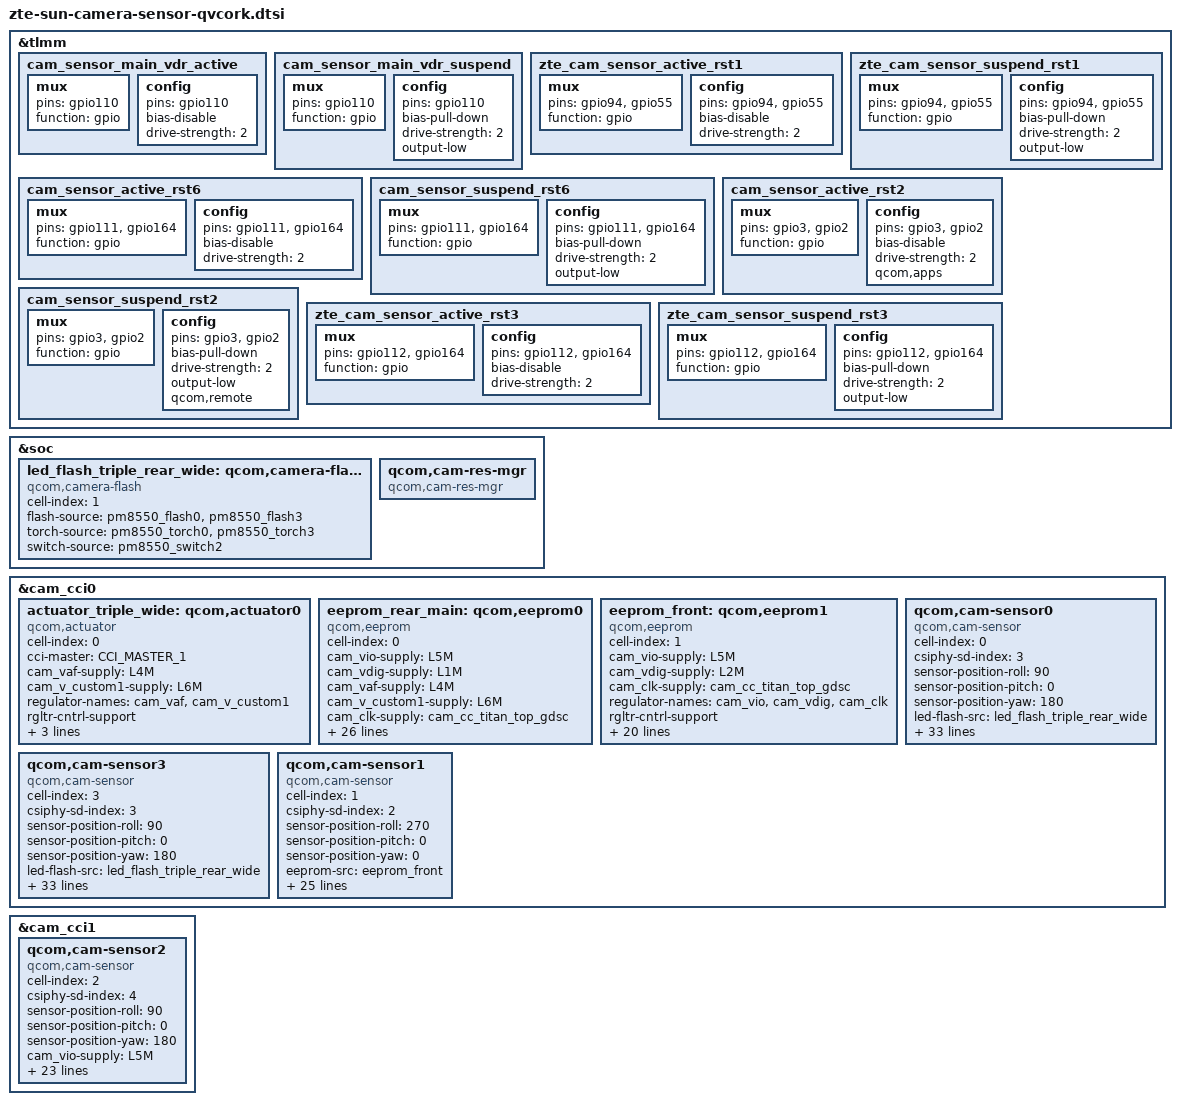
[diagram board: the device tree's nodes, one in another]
#include <dt-bindings/msm-camera.h>
&tlmm {
	cam_sensor_main_vdr_active: cam_sensor_main_vdr_active {
		mux {
			pins = "gpio110";
			function = "gpio";
		};
		config {
			pins = "gpio110";
			bias-disable; /* NO PULL */
			drive-strength = <2>; /* 2 MA */
		};
	};

	cam_sensor_main_vdr_suspend: cam_sensor_main_vdr_suspend {
		mux {
			pins ="gpio110";
			function = "gpio";
		};

		config {
			pins = "gpio110";
			bias-pull-down; /* PULL DOWN */
			drive-strength = <2>; /* 2 MA */
			output-low;
		};
	};

	zte_cam_sensor_active_rst1: zte_cam_sensor_active_rst1 {
		/* RESET 2 */
		mux {
			pins = "gpio94", "gpio55";
			function = "gpio";
		};

		config {
			pins = "gpio94", "gpio55";
			bias-disable; /* No PULL */
			drive-strength = <2>; /* 2 MA */
		};
	};

	zte_cam_sensor_suspend_rst1: zte_cam_sensor_suspend_rst1 {
		/* RESET 2 */
		mux {
			pins = "gpio94", "gpio55";
			function = "gpio";
		};

		config {
			pins = "gpio94", "gpio55";
			bias-pull-down; /* PULL DOWN */
			drive-strength = <2>; /* 2 MA */
			output-low;
		};
	};

	cam_sensor_active_rst6: cam_sensor_active_rst6 {
		/* RESET 2 */
		mux {
			pins = "gpio111", "gpio164";
			function = "gpio";
		};

		config {
			pins = "gpio111", "gpio164";
			bias-disable; /* No PULL */
			drive-strength = <2>; /* 2 MA */
		};
	};

	cam_sensor_suspend_rst6: cam_sensor_suspend_rst6 {
		/* RESET 2 */
		mux {
			pins = "gpio111", "gpio164";
			function = "gpio";
		};

		config {
			pins = "gpio111", "gpio164";
			bias-pull-down; /* PULL DOWN */
			drive-strength = <2>; /* 2 MA */
			output-low;
		};
	};

	cam_sensor_active_rst2: cam_sensor_active_rst2 {
		mux {
			pins = "gpio3", "gpio2";
			function = "gpio";
		};

		config {
			pins = "gpio3", "gpio2";
			bias-disable; /* No PULL */
			drive-strength = <2>; /* 2 MA */
			qcom,apps;
		};
	};

	cam_sensor_suspend_rst2: cam_sensor_suspend_rst2 {
		mux {
			pins = "gpio3", "gpio2";
			function = "gpio";
		};

		config {
			pins = "gpio3", "gpio2";
			bias-pull-down; /* PULL DOWN */
			drive-strength = <2>; /* 2 MA */
			output-low;
			qcom,remote;
		};
	};

	zte_cam_sensor_active_rst3: zte_cam_sensor_active_rst3 {
		/* RESET 2 */
		mux {
			pins = "gpio112", "gpio164";
			function = "gpio";
		};

		config {
			pins = "gpio112", "gpio164";
			bias-disable; /* No PULL */
			drive-strength = <2>; /* 2 MA */
		};
	};

	zte_cam_sensor_suspend_rst3: zte_cam_sensor_suspend_rst3 {
		/* RESET 2 */
		mux {
			pins = "gpio112", "gpio164";
			function = "gpio";
		};

		config {
			pins = "gpio112", "gpio164";
			bias-pull-down; /* PULL DOWN */
			drive-strength = <2>; /* 2 MA */
			output-low;
		};
	};
};

&soc {
	led_flash_triple_rear_wide: qcom,camera-flash1 {
		cell-index = <1>;
		compatible = "qcom,camera-flash";
		flash-source = <&pm8550_flash0 &pm8550_flash3>;
		torch-source = <&pm8550_torch0 &pm8550_torch3>;
		switch-source = <&pm8550_switch2>;
		status = "ok";
	};

	qcom,cam-res-mgr {
		compatible = "qcom,cam-res-mgr";
		status = "ok";
	};
};

&cam_cci0 {
	actuator_triple_wide: qcom,actuator0 {
		cell-index = <0>;
		compatible = "qcom,actuator";
		cci-master = <CCI_MASTER_1>;
		cam_vaf-supply = <&L4M>;
		cam_v_custom1-supply = <&L6M>;
		regulator-names = "cam_vaf", "cam_v_custom1";
		rgltr-cntrl-support;
		rgltr-min-voltage = <2800000 2800000>;
		rgltr-max-voltage = <2800000 2800000>;
		rgltr-load-current = <67700 140000>;
	};
	eeprom_rear_main: qcom,eeprom0 {
		cell-index = <0>;
		compatible = "qcom,eeprom";
		cam_vio-supply = <&L5M>;
		cam_vdig-supply = <&L1M>;
		cam_vaf-supply = <&L4M>;
		cam_v_custom1-supply = <&L6M>;
		cam_clk-supply = <&cam_cc_titan_top_gdsc>;
		regulator-names = "cam_vio", "cam_vdig", "cam_vaf", "cam_v_custom1", "cam_clk";
		rgltr-cntrl-support;
		rgltr-min-voltage = <1800000 1104000 2800000 2800000 0>;
		rgltr-max-voltage = <1800000 1104000 2800000 2800000 0>;
		rgltr-load-current = <155000 680000 67700 140000 0>;
		gpio-no-mux = <0>;
		pinctrl-names = "cam_default", "cam_suspend";
		pinctrl-0 = <&cam_sensor_mclk1_active
			&zte_cam_sensor_active_rst1>;
		pinctrl-1 = <&cam_sensor_mclk1_suspend
			&zte_cam_sensor_suspend_rst1>;
		gpios = <&tlmm 90 0>,
			<&tlmm 94 0>,
			<&tlmm 55 0>;
		gpio-reset = <1>;
		gpio-custom1 = <2>;
		gpio-req-tbl-num = <0 1 2>;
		gpio-req-tbl-flags = <1 0 0>;
		gpio-req-tbl-label = "CAMIF_MCLK1",
					"CAM_RESET1",
					"CAM_VANA1";
		cci-master = <CCI_MASTER_1>;
		clocks = <&cambistmclkcc CAM_BIST_MCLK_CC_MCLK1_CLK>;
		clock-names = "cam_clk";
		clock-cntl-level = "nominal";
		clock-rates = <24000000>;
		status = "ok";
	};

	eeprom_front: qcom,eeprom1 {
		cell-index = <1>;
		compatible = "qcom,eeprom";
		cam_vio-supply = <&L5M>;
		cam_vdig-supply = <&L2M>;
		cam_clk-supply = <&cam_cc_titan_top_gdsc>;
		regulator-names = "cam_vio", "cam_vdig", "cam_clk";
		rgltr-cntrl-support;
		rgltr-min-voltage = <1800000 1056000 0>;
		rgltr-max-voltage = <1800000 1056000 0>;
		rgltr-load-current = <4000 260700 0>;
		gpio-no-mux = <0>;
		pinctrl-names = "cam_default", "cam_suspend";
		pinctrl-0 = <&cam_sensor_mclk4_active
				 &cam_sensor_active_rst6>;
		pinctrl-1 = <&cam_sensor_mclk4_suspend
				 &cam_sensor_suspend_rst6>;
		gpios = <&tlmm 93 0>,
			<&tlmm 111 0>,
			<&tlmm 164 0>;
		gpio-reset = <1>;
		gpio-custom1 = <2>;
		gpio-req-tbl-num = <0 1 2>;
		gpio-req-tbl-flags = <1 0 0>;
		gpio-req-tbl-label = "CAMIF_MCLK4",
					"CAM_RESET6",
					"CAM_VANA6";
		cci-master = <CCI_MASTER_0>;
		clocks = <&cambistmclkcc CAM_BIST_MCLK_CC_MCLK4_CLK>;
		clock-names = "cam_clk";
		clock-cntl-level = "nominal";
		clock-rates = <24000000>;
		status = "ok";
	};

	qcom,cam-sensor0 {
		cell-index = <0>;
		compatible = "qcom,cam-sensor";
		csiphy-sd-index = <3>;
		sensor-position-roll = <90>;
		sensor-position-pitch = <0>;
		sensor-position-yaw = <180>;
		led-flash-src = <&led_flash_triple_rear_wide>;
		eeprom-src = <&eeprom_rear_main>;
		actuator-src = <&actuator_triple_wide>;
		cam_vio-supply = <&L5M>;
		cam_vdig-supply = <&L1M>;
		cam_vaf-supply = <&L4M>;
		cam_v_custom1-supply = <&L6M>;
		cam_clk-supply = <&cam_cc_titan_top_gdsc>;
		regulator-names = "cam_vio", "cam_vdig", "cam_vaf", "cam_v_custom1", "cam_clk";
		rgltr-cntrl-support;
		rgltr-min-voltage = <1800000 1104000 2800000 2800000 0>;
		rgltr-max-voltage = <1800000 1104000 2800000 2800000 0>;
		rgltr-load-current = <155000 680000 67700 140000 0>;
		gpio-no-mux = <0>;
		pinctrl-names = "cam_default", "cam_suspend";
		pinctrl-0 = <&cam_sensor_mclk1_active
			&zte_cam_sensor_active_rst1>;
		pinctrl-1 = <&cam_sensor_mclk1_suspend
			&zte_cam_sensor_suspend_rst1>;
		gpios = <&tlmm 90 0>,
			<&tlmm 94 0>,
			<&tlmm 55 0>;
		gpio-reset = <1>;
		gpio-custom1 = <2>;
		gpio-req-tbl-num = <0 1 2>;
		gpio-req-tbl-flags = <1 0 0>;
		gpio-req-tbl-label = "CAMIF_MCLK1",
					"CAM_RESET1",
					"CAM_VANA1";
		cci-master = <CCI_MASTER_1>;
		clocks = <&cambistmclkcc CAM_BIST_MCLK_CC_MCLK1_CLK>;
		clock-names = "cam_clk";
		clock-cntl-level = "nominal";
		clock-rates = <24000000>;
		status = "ok";
	};

	qcom,cam-sensor3 {
		cell-index = <3>;
		compatible = "qcom,cam-sensor";
		csiphy-sd-index = <3>;
		sensor-position-roll = <90>;
		sensor-position-pitch = <0>;
		sensor-position-yaw = <180>;
		led-flash-src = <&led_flash_triple_rear_wide>;
		eeprom-src = <&eeprom_rear_main>;
		actuator-src = <&actuator_triple_wide>;
		cam_vio-supply = <&L5M>;
		cam_vdig-supply = <&L1M>;
		cam_vaf-supply = <&L4M>;
		cam_v_custom1-supply = <&L6M>;
		cam_clk-supply = <&cam_cc_titan_top_gdsc>;
		regulator-names = "cam_vio", "cam_vdig", "cam_vaf", "cam_v_custom1", "cam_clk";
		rgltr-cntrl-support;
		rgltr-min-voltage = <1800000 1104000 2800000 2800000 0>;
		rgltr-max-voltage = <1800000 1104000 2800000 2800000 0>;
		rgltr-load-current = <155000 680000 67700 140000 0>;
		gpio-no-mux = <0>;
		pinctrl-names = "cam_default", "cam_suspend";
		pinctrl-0 = <&cam_sensor_mclk1_active
			&zte_cam_sensor_active_rst1>;
		pinctrl-1 = <&cam_sensor_mclk1_suspend
			&zte_cam_sensor_suspend_rst1>;
		gpios = <&tlmm 90 0>,
			<&tlmm 94 0>,
			<&tlmm 55 0>;
		gpio-reset = <1>;
		gpio-custom1 = <2>;
		gpio-req-tbl-num = <0 1 2>;
		gpio-req-tbl-flags = <1 0 0>;
		gpio-req-tbl-label = "CAMIF_MCLK1",
					"CAM_RESET1",
					"CAM_VANA1";
		cci-master = <CCI_MASTER_1>;
		clocks = <&cambistmclkcc CAM_BIST_MCLK_CC_MCLK1_CLK>;
		clock-names = "cam_clk";
		clock-cntl-level = "nominal";
		clock-rates = <24000000>;
		status = "ok";
	};

	qcom,cam-sensor1 {
		cell-index = <1>;
		compatible = "qcom,cam-sensor";
		csiphy-sd-index = <2>;
		sensor-position-roll = <270>;
		sensor-position-pitch = <0>;
		sensor-position-yaw = <0>;
		eeprom-src = <&eeprom_front>;
		cam_vio-supply = <&L5M>;
		cam_vdig-supply = <&L2M>;
		cam_clk-supply = <&cam_cc_titan_top_gdsc>;
		regulator-names = "cam_vio", "cam_vdig", "cam_clk";
		rgltr-cntrl-support;
		rgltr-min-voltage = <1800000 1056000 0>;
		rgltr-max-voltage = <1800000 1056000 0>;
		rgltr-load-current = <4000 260700 0>;
		gpio-no-mux = <0>;
		pinctrl-names = "cam_default", "cam_suspend";
		pinctrl-0 = <&cam_sensor_mclk4_active
				 &cam_sensor_active_rst6>;
		pinctrl-1 = <&cam_sensor_mclk4_suspend
				 &cam_sensor_suspend_rst6>;
		gpios = <&tlmm 93 0>,
			<&tlmm 111 0>,
			<&tlmm 164 0>;
		gpio-reset = <1>;
		gpio-custom1 = <2>;
		gpio-req-tbl-num = <0 1 2>;
		gpio-req-tbl-flags = <1 0 0>;
		gpio-req-tbl-label = "CAMIF_MCLK4",
					"CAM_RESET6",
					"CAM_VANA6";
		cci-master = <CCI_MASTER_0>;
		clocks = <&cambistmclkcc CAM_BIST_MCLK_CC_MCLK4_CLK>;
		clock-names = "cam_clk";
		clock-cntl-level = "nominal";
		clock-rates = <24000000>;
		status = "ok";
	};
};

&cam_cci1 {
	qcom,cam-sensor2 {
		cell-index = <2>;
		compatible = "qcom,cam-sensor";
		csiphy-sd-index = <4>;
		sensor-position-roll = <90>;
		sensor-position-pitch = <0>;
		sensor-position-yaw = <180>;
		cam_vio-supply = <&L5M>;
		cam_clk-supply = <&cam_cc_titan_top_gdsc>;
		regulator-names = "cam_vio", "cam_clk";
		rgltr-cntrl-support;
		rgltr-min-voltage = <1800000 0>;
		rgltr-max-voltage = <1800000 0>;
		rgltr-load-current = <4000 0>;
		gpio-no-mux = <0>;
		pinctrl-names = "cam_default", "cam_suspend";
		pinctrl-0 = <&cam_sensor_mclk2_active
				 &cam_sensor_active_rst2>;
		pinctrl-1 = <&cam_sensor_mclk2_suspend
				 &cam_sensor_suspend_rst2>;
		gpios = <&tlmm 91 0>,
			<&tlmm 3 0>,
			<&tlmm 2 0>;
		gpio-reset = <1>;
		gpio-custom1 = <2>;
		gpio-req-tbl-num = <0 1 2>;
		gpio-req-tbl-flags = <1 0 0>;
		gpio-req-tbl-label = "CAMIF_MCLK2",
					"CAM_RESET2",
					"CAM_VANA2";
		cci-master = <CCI_MASTER_0>;
		clocks = <&cambistmclkcc CAM_BIST_MCLK_CC_MCLK2_CLK>;
		clock-names = "cam_clk";
		clock-cntl-level = "nominal";
		clock-rates = <24000000>;
		status = "ok";
	};
};
